VERSION ""

NS_ :

BS_:

BU_:

BO_ 3221225472 VECTOR__INDEPENDENT_SIG_MSG: 0 Vector__XXX
 SG_ New_Signal_69 : 0|8@1- (1,0) [0|0] "" Vector__XXX
 SG_ DebugSignal8 : 0|8@1+ (1,-100) [-100|155] "" Vector__XXX
 SG_ DebugSignal7 : 0|8@1+ (1,-100) [-100|155] "" Vector__XXX
 SG_ DebugSignal6 : 0|8@1+ (1,-100) [-100|155] "" Vector__XXX
 SG_ DebugSignal5 : 0|8@1+ (1,-100) [-100|155] "" Vector__XXX
 SG_ DebugSignal4 : 0|8@1+ (1,-100) [-100|155] "" Vector__XXX
 SG_ DebugSignal3 : 0|8@1+ (1,-100) [-100|155] "" Vector__XXX
 SG_ DebugSignal2 : 0|8@1+ (1,-100) [-100|155] "" Vector__XXX
 SG_ DebugSignal1 : 0|8@1+ (1,-100) [-100|155] "" Vector__XXX

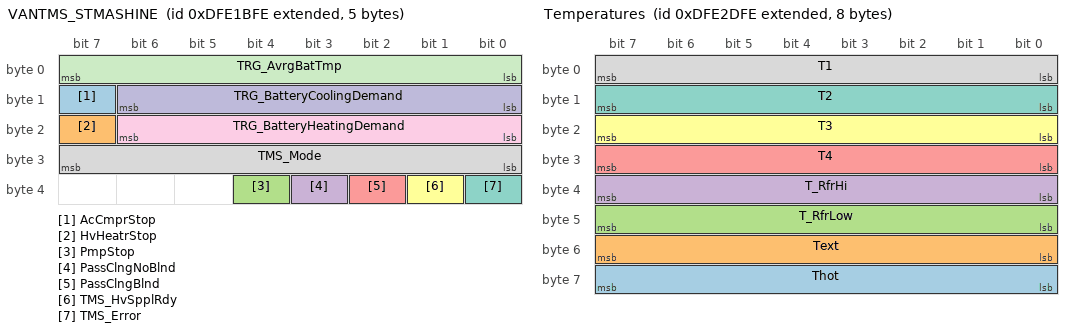
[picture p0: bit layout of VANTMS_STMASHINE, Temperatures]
BO_ 2382240766 VANTMS_STMASHINE: 5 Vector__XXX
 SG_ AcCmprStop : 15|1@1+ (1,0) [0|1] "" Vector__XXX
 SG_ HvHeatrStop : 23|1@1+ (1,0) [0|1] "" Vector__XXX
 SG_ PmpStop : 36|1@1+ (1,0) [0|1] "" Vector__XXX
 SG_ PassClngNoBlnd : 35|1@1+ (1,0) [0|1] "" Vector__XXX
 SG_ PassClngBlnd : 34|1@1+ (1,0) [0|1] "" Vector__XXX
 SG_ TMS_HvSpplRdy : 33|1@1+ (1,0) [0|1] "" Vector__XXX
 SG_ TMS_Error : 32|1@1+ (1,0) [0|1] "" Vector__XXX
 SG_ TMS_Mode : 24|8@1+ (1,0) [0|255] "" Vector__XXX
 SG_ TRG_BatteryHeatingDemand : 16|7@1+ (1,0) [0|100] "" Vector__XXX
 SG_ TRG_BatteryCoolingDemand : 8|7@1+ (1,0) [0|100] "" Vector__XXX
 SG_ TRG_AvrgBatTmp : 0|8@1+ (1,-40) [-40|215] "" Vector__XXX

BO_ 2382245374 Temperatures: 8 Vector__XXX
 SG_ Thot : 56|8@1+ (1,-40) [-40|200] "" Vector__XXX
 SG_ Text : 48|8@1+ (1,-40) [-40|200] "" Vector__XXX
 SG_ T_RfrLow : 40|8@1+ (1,-40) [-40|200] "" Vector__XXX
 SG_ T_RfrHi : 32|8@1+ (1,-40) [-40|200] "" Vector__XXX
 SG_ T4 : 24|8@1+ (1,-40) [-40|200] "" Vector__XXX
 SG_ T3 : 16|8@1+ (1,-40) [-40|200] "" Vector__XXX
 SG_ T2 : 8|8@1+ (1,-40) [-40|200] "" Vector__XXX
 SG_ T1 : 0|8@1+ (1,-40) [-40|200] "" Vector__XXX

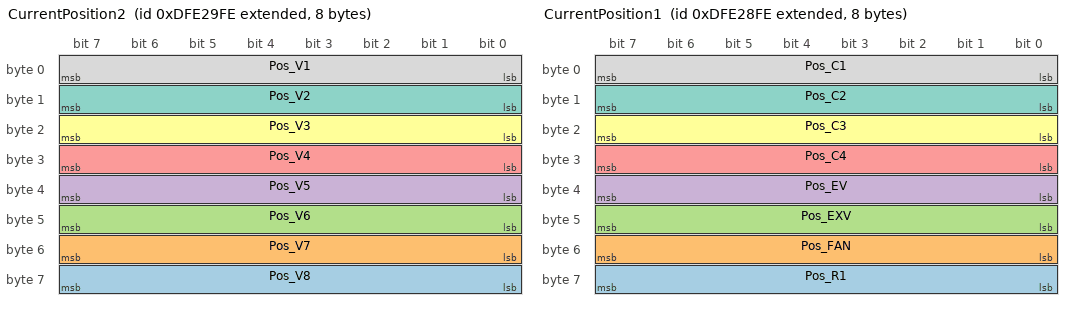
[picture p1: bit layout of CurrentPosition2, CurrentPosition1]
BO_ 2382244350 CurrentPosition2: 8 Vector__XXX
 SG_ Pos_V8 : 56|8@1+ (1,0) [0|100] "" Vector__XXX
 SG_ Pos_V7 : 48|8@1+ (1,0) [0|100] "" Vector__XXX
 SG_ Pos_V6 : 40|8@1+ (1,0) [0|100] "" Vector__XXX
 SG_ Pos_V5 : 32|8@1+ (1,0) [0|100] "" Vector__XXX
 SG_ Pos_V4 : 24|8@1+ (1,0) [0|100] "" Vector__XXX
 SG_ Pos_V3 : 16|8@1+ (1,0) [0|100] "" Vector__XXX
 SG_ Pos_V2 : 8|8@1+ (1,0) [0|100] "" Vector__XXX
 SG_ Pos_V1 : 0|8@1+ (1,0) [0|100] "" Vector__XXX

BO_ 2382244094 CurrentPosition1: 8 Vector__XXX
 SG_ Pos_R1 : 56|8@1+ (1,0) [0|100] "" Vector__XXX
 SG_ Pos_FAN : 48|8@1+ (1,0) [0|100] "" Vector__XXX
 SG_ Pos_EXV : 40|8@1+ (1,0) [0|100] "" Vector__XXX
 SG_ Pos_EV : 32|8@1+ (1,0) [0|100] "" Vector__XXX
 SG_ Pos_C4 : 24|8@1+ (1,0) [0|100] "" Vector__XXX
 SG_ Pos_C3 : 16|8@1+ (1,0) [0|100] "" Vector__XXX
 SG_ Pos_C2 : 8|8@1+ (1,0) [0|100] "" Vector__XXX
 SG_ Pos_C1 : 0|8@1+ (1,0) [0|100] "" Vector__XXX

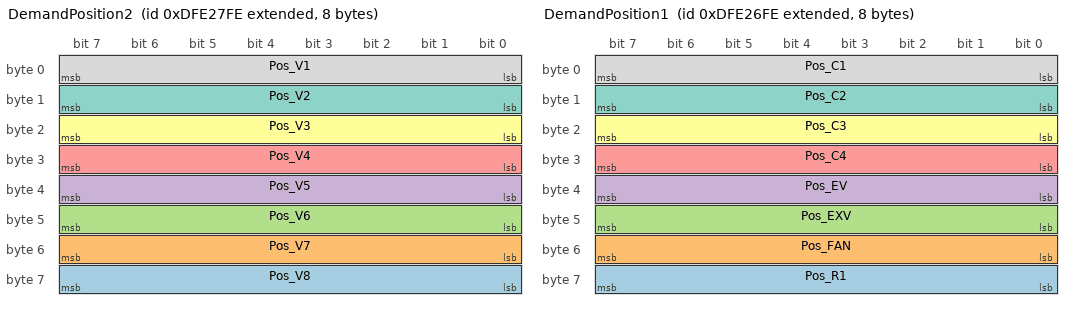
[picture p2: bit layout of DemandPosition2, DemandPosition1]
BO_ 2382243838 DemandPosition2: 8 Vector__XXX
 SG_ Pos_V8 : 56|8@1+ (1,0) [0|100] "" Vector__XXX
 SG_ Pos_V7 : 48|8@1+ (1,0) [0|100] "" Vector__XXX
 SG_ Pos_V6 : 40|8@1+ (1,0) [0|100] "" Vector__XXX
 SG_ Pos_V5 : 32|8@1+ (1,0) [0|100] "" Vector__XXX
 SG_ Pos_V4 : 24|8@1+ (1,0) [0|100] "" Vector__XXX
 SG_ Pos_V3 : 16|8@1+ (1,0) [0|100] "" Vector__XXX
 SG_ Pos_V2 : 8|8@1+ (1,0) [0|100] "" Vector__XXX
 SG_ Pos_V1 : 0|8@1+ (1,0) [0|100] "" Vector__XXX

BO_ 2382243582 DemandPosition1: 8 Vector__XXX
 SG_ Pos_R1 : 56|8@1+ (1,0) [0|100] "" Vector__XXX
 SG_ Pos_FAN : 48|8@1+ (1,0) [0|100] "" Vector__XXX
 SG_ Pos_EXV : 40|8@1+ (1,0) [0|100] "" Vector__XXX
 SG_ Pos_EV : 32|8@1+ (1,0) [0|100] "" Vector__XXX
 SG_ Pos_C4 : 24|8@1+ (1,0) [0|100] "" Vector__XXX
 SG_ Pos_C3 : 16|8@1+ (1,0) [0|100] "" Vector__XXX
 SG_ Pos_C2 : 8|8@1+ (1,0) [0|100] "" Vector__XXX
 SG_ Pos_C1 : 0|8@1+ (1,0) [0|100] "" Vector__XXX

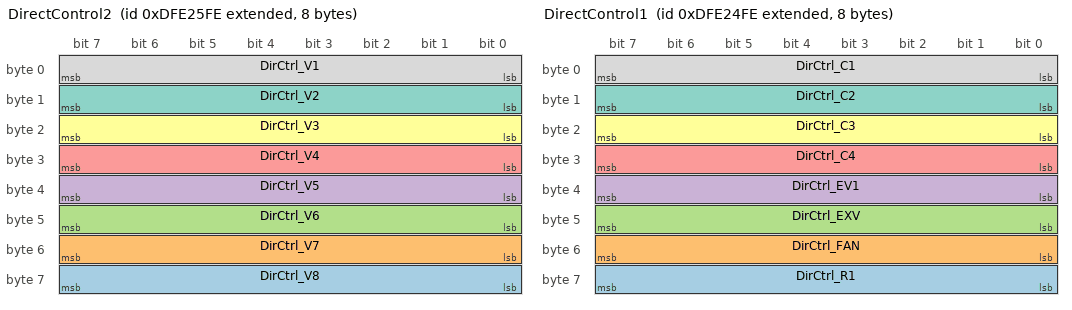
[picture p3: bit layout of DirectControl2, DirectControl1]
BO_ 2382243326 DirectControl2: 8 Vector__XXX
 SG_ DirCtrl_V8 : 56|8@1+ (1,0) [0|100] "" Vector__XXX
 SG_ DirCtrl_V7 : 48|8@1+ (1,0) [0|100] "" Vector__XXX
 SG_ DirCtrl_V6 : 40|8@1+ (1,0) [0|100] "" Vector__XXX
 SG_ DirCtrl_V5 : 32|8@1+ (1,0) [0|100] "" Vector__XXX
 SG_ DirCtrl_V4 : 24|8@1+ (1,0) [0|100] "" Vector__XXX
 SG_ DirCtrl_V3 : 16|8@1+ (1,0) [0|100] "" Vector__XXX
 SG_ DirCtrl_V2 : 8|8@1+ (1,0) [0|100] "" Vector__XXX
 SG_ DirCtrl_V1 : 0|8@1+ (1,0) [0|100] "" Vector__XXX

BO_ 2382243070 DirectControl1: 8 Vector__XXX
 SG_ DirCtrl_R1 : 56|8@1+ (1,0) [0|100] "" Vector__XXX
 SG_ DirCtrl_FAN : 48|8@1+ (1,0) [0|100] "" Vector__XXX
 SG_ DirCtrl_EXV : 40|8@1+ (1,0) [0|100] "" Vector__XXX
 SG_ DirCtrl_EV1 : 32|8@1+ (1,0) [0|100] "" Vector__XXX
 SG_ DirCtrl_C4 : 24|8@1+ (1,0) [0|100] "" Vector__XXX
 SG_ DirCtrl_C3 : 16|8@1+ (1,0) [0|100] "" Vector__XXX
 SG_ DirCtrl_C2 : 8|8@1+ (1,0) [0|100] "" Vector__XXX
 SG_ DirCtrl_C1 : 0|8@1+ (1,0) [0|100] "" Vector__XXX

BO_ 2382242558 Temperatures2: 8 Vector__XXX
 SG_ T2E : 0|8@1+ (1,-40) [-40|200] "" Vector__XXX

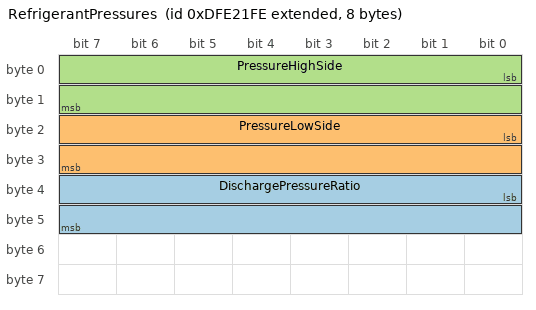
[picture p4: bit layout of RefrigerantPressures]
BO_ 2382242302 RefrigerantPressures: 8 Vector__XXX
 SG_ DischargePressureRatio : 32|16@1+ (1,0) [0|65535] "%" Vector__XXX
 SG_ PressureLowSide : 16|16@1+ (1,0) [0|60000] "kPa" Vector__XXX
 SG_ PressureHighSide : 0|16@1+ (1,0) [0|60000] "kPa" Vector__XXX

BO_ 2382241022 RoutineOperation: 8 Vector__XXX
 SG_ RoutineResponse : 4|4@1+ (1,0) [0|15] "" Vector__XXX
 SG_ RoutineRequest : 0|4@1+ (1,0) [0|15] "" Vector__XXX

CM_ "$File: //depot/auto/dbc/StaticInternal/TMS/VanThermal/0.1.0.0/VanThermal_int.dbc $
$Change: 215787 $
$DateTime: 2024/08/14 10:44:28 $
$Revision: #1 $";
CM_ BO_ 3221225472 "This is a message for not used signals, created by Vector CANdb++ DBC OLE DB Provider.";
BA_DEF_ SG_  "SigType" ENUM  "Default","Range","RangeSigned","ASCII","Discrete","Control","ReferencePGN","DTC","StringDelimiter","StringLength","StringLengthControl","MessageCounter","MessageChecksum";
BA_DEF_ SG_  "GenSigEVName" STRING ;
BA_DEF_ SG_  "GenSigILSupport" ENUM  "No","Yes";
BA_DEF_ SG_  "GenSigSendType" ENUM  "Cyclic","OnWrite","OnWriteWithRepetition","OnChange","OnChangeWithRepetition","IfActive","IfActiveWithRepetition","NoSigSendType";
BA_DEF_ SG_  "GenSigStartValue" INT 0 2147483647;
BA_DEF_ BO_  "GenMsgILSupport" ENUM  "No","Yes";
BA_DEF_ BU_  "NmStationAddress" INT 0 255;
BA_DEF_ BO_  "GenMsgSendType" ENUM  "cyclic","NotUsed","IfActive","NotUsed","NotUsed","NotUsed","NotUsed","NotUsed","noMsgSendType";
BA_DEF_ BO_  "GenMsgRequestable" INT 0 1;
BA_DEF_ BO_  "GenMsgCycleTime" INT 0 3600000;
BA_DEF_ BO_  "Producer" STRING ;
BA_DEF_  "DBName" STRING ;
BA_DEF_  "BusType" STRING ;
BA_DEF_  "ProtocolType" STRING ;
BA_DEF_ BO_  "VFrameFormat" ENUM  "StandardCAN","ExtendedCAN","reserved","J1939PG";
BA_DEF_DEF_  "SigType" "Default";
BA_DEF_DEF_  "GenSigEVName" "Env@Nodename_@Signame";
BA_DEF_DEF_  "GenSigILSupport" "Yes";
BA_DEF_DEF_  "GenSigSendType" "NoSigSendType";
BA_DEF_DEF_  "GenSigStartValue" 0;
BA_DEF_DEF_  "GenMsgILSupport" "Yes";
BA_DEF_DEF_  "NmStationAddress" 254;
BA_DEF_DEF_  "GenMsgSendType" "noMsgSendType";
BA_DEF_DEF_  "GenMsgRequestable" 1;
BA_DEF_DEF_  "GenMsgCycleTime" 0;
BA_DEF_DEF_  "Producer" "TMS";
BA_DEF_DEF_  "DBName" "VanThermal_int";
BA_DEF_DEF_  "BusType" "CAN";
BA_DEF_DEF_  "ProtocolType" "J1939";
BA_DEF_DEF_  "VFrameFormat" "J1939PG";
BA_ "GenMsgSendType" BO_ 2382240766 0;
BA_ "GenMsgCycleTime" BO_ 2382240766 100;
BA_ "GenMsgCycleTime" BO_ 2382245374 250;
BA_ "GenMsgSendType" BO_ 2382245374 0;
BA_ "GenMsgSendType" BO_ 2382244350 0;
BA_ "GenMsgCycleTime" BO_ 2382244350 250;
BA_ "GenMsgSendType" BO_ 2382244094 0;
BA_ "GenMsgCycleTime" BO_ 2382244094 250;
BA_ "GenMsgSendType" BO_ 2382243838 0;
BA_ "GenMsgCycleTime" BO_ 2382243838 250;
BA_ "GenMsgCycleTime" BO_ 2382243582 250;
BA_ "GenMsgSendType" BO_ 2382243582 0;
BA_ "GenMsgSendType" BO_ 2382243326 0;
BA_ "GenMsgCycleTime" BO_ 2382243326 100;
BA_ "GenMsgSendType" BO_ 2382243070 0;
BA_ "GenMsgCycleTime" BO_ 2382243070 100;
BA_ "GenMsgCycleTime" BO_ 2382242558 250;
BA_ "GenMsgSendType" BO_ 2382242558 0;
BA_ "GenMsgCycleTime" BO_ 2382242302 250;
BA_ "GenMsgSendType" BO_ 2382242302 0;
BA_ "GenMsgCycleTime" BO_ 2382241022 250;
BA_ "GenMsgSendType" BO_ 2382241022 0;
BA_ "GenSigStartValue" SG_ 3221225472 DebugSignal8 100;
BA_ "GenSigStartValue" SG_ 3221225472 DebugSignal7 100;
BA_ "GenSigStartValue" SG_ 3221225472 DebugSignal6 100;
BA_ "GenSigStartValue" SG_ 3221225472 DebugSignal5 100;
BA_ "GenSigStartValue" SG_ 3221225472 DebugSignal4 100;
BA_ "GenSigStartValue" SG_ 3221225472 DebugSignal3 100;
BA_ "GenSigStartValue" SG_ 3221225472 DebugSignal2 100;
BA_ "GenSigStartValue" SG_ 3221225472 DebugSignal1 100;
BA_ "GenSigStartValue" SG_ 2382240766 TRG_AvrgBatTmp 40;
BA_ "SigType" SG_ 2382245374 Thot 1;
BA_ "GenSigStartValue" SG_ 2382245374 Thot 40;
BA_ "SigType" SG_ 2382245374 Text 1;
BA_ "GenSigStartValue" SG_ 2382245374 Text 40;
BA_ "SigType" SG_ 2382245374 T_RfrLow 1;
BA_ "GenSigStartValue" SG_ 2382245374 T_RfrLow 40;
BA_ "SigType" SG_ 2382245374 T_RfrHi 1;
BA_ "GenSigStartValue" SG_ 2382245374 T_RfrHi 40;
BA_ "SigType" SG_ 2382245374 T4 1;
BA_ "GenSigStartValue" SG_ 2382245374 T4 40;
BA_ "SigType" SG_ 2382245374 T3 1;
BA_ "GenSigStartValue" SG_ 2382245374 T3 40;
BA_ "SigType" SG_ 2382245374 T2 1;
BA_ "GenSigStartValue" SG_ 2382245374 T2 40;
BA_ "SigType" SG_ 2382245374 T1 1;
BA_ "GenSigStartValue" SG_ 2382245374 T1 40;
BA_ "SigType" SG_ 2382244350 Pos_V8 1;
BA_ "SigType" SG_ 2382244350 Pos_V7 1;
BA_ "SigType" SG_ 2382244350 Pos_V6 1;
BA_ "SigType" SG_ 2382244350 Pos_V5 1;
BA_ "SigType" SG_ 2382244350 Pos_V4 1;
BA_ "SigType" SG_ 2382244350 Pos_V3 1;
BA_ "SigType" SG_ 2382244350 Pos_V2 1;
BA_ "SigType" SG_ 2382244350 Pos_V1 1;
BA_ "SigType" SG_ 2382244094 Pos_R1 1;
BA_ "SigType" SG_ 2382244094 Pos_FAN 1;
BA_ "SigType" SG_ 2382244094 Pos_EXV 1;
BA_ "SigType" SG_ 2382244094 Pos_EV 1;
BA_ "SigType" SG_ 2382244094 Pos_C4 1;
BA_ "SigType" SG_ 2382244094 Pos_C3 1;
BA_ "SigType" SG_ 2382244094 Pos_C2 1;
BA_ "SigType" SG_ 2382244094 Pos_C1 1;
BA_ "SigType" SG_ 2382243838 Pos_V8 1;
BA_ "SigType" SG_ 2382243838 Pos_V7 1;
BA_ "SigType" SG_ 2382243838 Pos_V6 1;
BA_ "SigType" SG_ 2382243838 Pos_V5 1;
BA_ "SigType" SG_ 2382243838 Pos_V4 1;
BA_ "SigType" SG_ 2382243838 Pos_V3 1;
BA_ "SigType" SG_ 2382243838 Pos_V2 1;
BA_ "SigType" SG_ 2382243838 Pos_V1 1;
BA_ "SigType" SG_ 2382243582 Pos_R1 1;
BA_ "SigType" SG_ 2382243582 Pos_FAN 1;
BA_ "SigType" SG_ 2382243582 Pos_EXV 1;
BA_ "SigType" SG_ 2382243582 Pos_EV 1;
BA_ "SigType" SG_ 2382243582 Pos_C4 1;
BA_ "SigType" SG_ 2382243582 Pos_C3 1;
BA_ "SigType" SG_ 2382243582 Pos_C2 1;
BA_ "SigType" SG_ 2382243582 Pos_C1 1;
BA_ "SigType" SG_ 2382242558 T2E 1;
BA_ "GenSigStartValue" SG_ 2382242558 T2E 40;
BA_ "SigType" SG_ 2382242302 DischargePressureRatio 1;
BA_ "SigType" SG_ 2382242302 PressureLowSide 1;
BA_ "SigType" SG_ 2382242302 PressureHighSide 1;
VAL_ 2382241022 RoutineResponse 11 "RtRsp_Service_Exit" 10 "RtRsp_Degas2_Finished" 9 "RtRsp_Degas1_Finished" 8 "RtRsp_DryFill_Finished" 7 "RtRsp_Degas2_PrcndPass" 6 "RtRsp_Degas2_PrcndAct" 5 "RtRsp_Degas1_PrcndPass" 4 "RtRsp_Degas1_PrcndAct" 3 "RtRsp_DryFill_PrcndPass" 2 "RtRsp_DryFill_PrcndAct" 1 "RtRsp_RoutineAbort" 0 "RtRsp_ServiceCnfrmd" ;
VAL_ 2382241022 RoutineRequest 8 "RtnReq_RoutineExit" 7 "RtnReq_CancelRoutine" 6 "RtnReq_Degas2_ComAct" 5 "RtnReq_Degas2_PreAct" 4 "RtnReq_Degas1_ComAct" 3 "RtnReq_Degas1_PreAct" 2 "RtnReq_DryFil_ComAct" 1 "RtnReq_DryFil_PreAct" 0 "RtnReq_ServiceReq" ;
